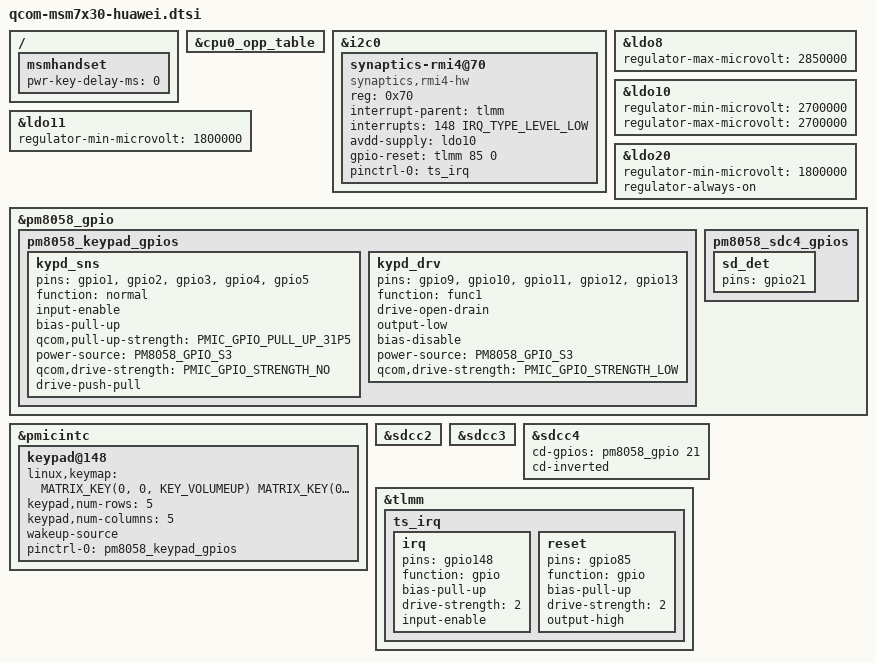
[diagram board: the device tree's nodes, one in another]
#include "qcom-msm7x30.dtsi"

#include <dt-bindings/input/input.h>

/ {
	msmhandset {
		pwr-key-delay-ms = <0>; /* 0 will disable end key */
	};
};

&cpu0_opp_table {
	/delete-node/ opp@24576000;
	/delete-node/ opp@61440000;
};

&i2c0 {
	synaptics-rmi4@70 {
		compatible = "synaptics,rmi4-hw";
		reg = <0x70>;
		interrupt-parent = <&tlmm>;
		interrupts = <148 IRQ_TYPE_LEVEL_LOW>;

		avdd-supply = <&ldo10>;

		gpio-reset = <&tlmm 85 0>;

		pinctrl-names = "default";
		pinctrl-0 = <&ts_irq>;
	};
};

&ldo8 {
	regulator-max-microvolt = <2850000>;
};

&ldo10 {
	regulator-min-microvolt = <2700000>;
	regulator-max-microvolt = <2700000>;
};

&ldo11 {
	regulator-min-microvolt = <1800000>;
};

&ldo20 {
	regulator-min-microvolt = <1800000>;
	regulator-always-on;
};

&pm8058_gpio {
	pm8058_keypad_gpios:pm8058_keypad_gpios {
		kypd_sns {
			pins = "gpio1", "gpio2", "gpio3", "gpio4", "gpio5";
			function = "normal";
			input-enable;
			bias-pull-up;
			qcom,pull-up-strength = <PMIC_GPIO_PULL_UP_31P5>;
			power-source = <PM8058_GPIO_S3>;
			qcom,drive-strength = <PMIC_GPIO_STRENGTH_NO>;
			drive-push-pull;
		};
		kypd_drv {
			pins = "gpio9", "gpio10", "gpio11", "gpio12", "gpio13";
			function = "func1";
			drive-open-drain;
			output-low;
			bias-disable;
			power-source = <PM8058_GPIO_S3>;
			qcom,drive-strength = <PMIC_GPIO_STRENGTH_LOW>;
		};
	};

	pm8058_sdc4_gpios:pm8058_sdc4_gpios {
		sd_det {
			pins = "gpio21";
		};
	};
};

&pmicintc {
	keypad@148 {
		linux,keymap = <
			MATRIX_KEY(0, 0, KEY_VOLUMEUP)
			MATRIX_KEY(0, 1, KEY_VOLUMEDOWN)
			>;
		keypad,num-rows = <5>;
		keypad,num-columns = <5>;
		wakeup-source;

		pinctrl-names = "default";
		pinctrl-0 = <&pm8058_keypad_gpios>;
	};
};

/* eMMC */
&sdcc2 {
	status = "ok";
};

/* Wi-Fi */
&sdcc3 {
	status = "ok";
};

/* External micro SD card */
&sdcc4 {
	status = "ok";
	cd-gpios = <&pm8058_gpio 21 0>;
	cd-inverted;
};

&tlmm {
	ts_irq:ts_irq {
		irq {
			pins = "gpio148";
			function = "gpio";
			bias-pull-up;
			drive-strength = <2>;
			input-enable;
		};
		reset {
			pins = "gpio85";
			function = "gpio";
			bias-pull-up;
			drive-strength = <2>;
			output-high;
		};
	};
};
